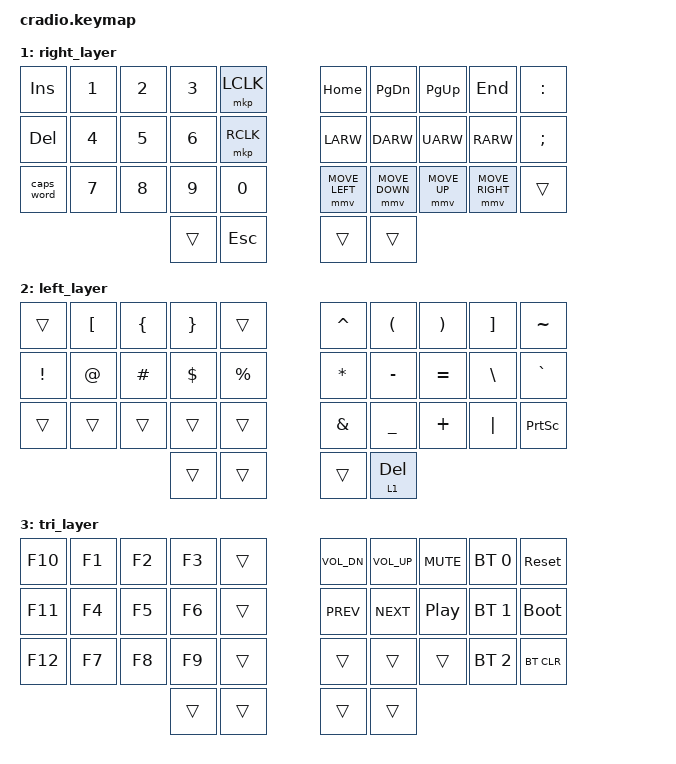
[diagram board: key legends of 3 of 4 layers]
// Copyright (c) 2022 The ZMK Contributors
// SPDX-License-Identifier: MIT

#include <behaviors.dtsi>
#include <dt-bindings/zmk/keys.h>
#include <dt-bindings/zmk/bt.h>
#include <dt-bindings/zmk/pointing.h>

// Home row mods macro
#define HRML(k1,k2,k3,k4) &ht LSHFT k1  &ht LCTRL k2  &ht LALT k3  &ht LGUI k4
#define HRMR(k1,k2,k3,k4) &ht RGUI k1  &ht RALT k2  &ht RCTRL k3  &ht RSHFT k4

/ {
    behaviors {
        ht: hold_tap {
            label = "hold_tap";
            compatible = "zmk,behavior-hold-tap";
            #binding-cells = <2>;
            flavor = "tap-preferred";
            tapping-term-ms = <220>;
            quick-tap-ms = <150>;
            require-prior-idle-ms = <100>;
            bindings = <&kp>, <&kp>;
        };

        // Dead key: send Compose + one key; the next key typed completes it.
        // &dead SQT -> Compose ' -> then e = é, E = É (see ~/.XCompose for n ? ! s)
        dead: dead_key {
            compatible = "zmk,behavior-macro-one-param";
            #binding-cells = <1>;
            bindings
                = <&kp CAPS>
                , <&macro_param_1to1>, <&kp MACRO_PLACEHOLDER>
                ;
        };
    };

    conditional_layers {
        compatible = "zmk,conditional-layers";
        tri_layer {
            if-layers = <1 2>;
            then-layer = <3>;
        };
    };

    combos {
        compatible = "zmk,combos";
        combo_tmux {
            timeout-ms = <50>;
            key-positions = <11 12>;  // S + D = Ctrl+A (tmux prefix)
            bindings = <&kp LC(A)>;
        };
        combo_acute {
            timeout-ms = <50>;
            key-positions = <2 12>;   // E + D = accent: then vowel → á é í ó ú, n → ñ, ? → ¿, ! → ¡
            bindings = <&dead SQT>;
        };
        combo_umlaut {
            timeout-ms = <50>;
            key-positions = <6 16>;   // U + J = umlaut: then vowel → ä ö ü, s → ß
            bindings = <&dead DQT>;
        };
        combo_compose {
            timeout-ms = <50>;
            key-positions = <12 13>;  // D + F = Compose key, for any other Compose sequence
            bindings = <&kp CAPS>;
        };
    };

    keymap {
        compatible = "zmk,keymap";
        default_layer {
            bindings = <
        //╭──────────┬──────────┬──────────┬──────────┬──────────╮   ╭──────────┬──────────┬──────────┬──────────┬──────────╮
        //│  Q       │  W       │  E       │  R       │  T       │   │  Y       │  U       │  I       │  O       │  P       │
            &kp Q      &kp W      &kp E      &kp R      &kp T          &kp Y      &kp U      &kp I      &kp O      &kp P
        //├──────────┼──────────┼──────────┼──────────┼──────────┤   ├──────────┼──────────┼──────────┼──────────┼──────────┤
        //│  A       │  S       │  D       │  F       │  G       │   │  H       │  J       │  K       │  L       │ ' "      │
            HRML(A,        S,         D,         F)     &kp G          &kp H      HRMR(J,        K,         L,        SQT)
        //├──────────┼──────────┼──────────┼──────────┼──────────┤   ├──────────┼──────────┼──────────┼──────────┼──────────┤
        //│  Z       │  X       │  C       │  V       │  B       │   │  N       │  M       │ , <      │ . >      │ / ?      │
            &kp Z      &kp X      &kp C      &kp V      &kp B          &kp N      &kp M      &kp COMMA  &kp DOT    &kp FSLH
        //╰──────────┴──────────┴──────────┼──────────┼──────────┤   ├──────────┼──────────┼──────────┴──────────┴──────────╯
                                            &lt 2 TAB   &kp ENTER     &kp SPACE  &lt 1 BSPC
        //                                 ╰──────────┴──────────╯   ╰──────────┴──────────╯
            >;
        };

        right_layer {
            bindings = <
        //╭──────────┬──────────┬──────────┬──────────┬──────────╮   ╭──────────┬──────────┬──────────┬──────────┬──────────╮
        //│ INSERT   │  1       │  2       │  3       │ LEFT CLK │   │ HOME     │ PAGE DN  │ PAGE UP  │ END      │  :       │
            &kp INS    &kp N1     &kp N2     &kp N3     &mkp LCLK      &kp HOME   &kp PG_DN  &kp PG_UP  &kp END    &kp COLON
        //├──────────┼──────────┼──────────┼──────────┼──────────┤   ├──────────┼──────────┼──────────┼──────────┼──────────┤
        //│ DELETE   │  4       │  5       │  6       │ RIGHT CLK│   │ LEFT     │ DOWN     │ UP       │ RIGHT    │  ;       │
            &kp DEL    &kp N4     &kp N5     &kp N6     &mkp RCLK      &kp LARW   &kp DARW   &kp UARW   &kp RARW   &kp SEMI
        //├──────────┼──────────┼──────────┼──────────┼──────────┤   ├──────────┼──────────┼──────────┼──────────┼──────────┤
        //│ CAPS     │  7       │  8       │  9       │  0       │   │ MS LEFT  │ MS DOWN  │ MS UP    │ MS RIGHT │          │
           &caps_word  &kp N7     &kp N8     &kp N9     &kp N0     &mmv MOVE_LEFT &mmv MOVE_DOWN &mmv MOVE_UP &mmv MOVE_RIGHT &trans
        //╰──────────┴──────────┴──────────┼──────────┼──────────┤   ├──────────┼──────────┼──────────┴──────────┴──────────╯
                                             &trans     &kp ESC        &trans     &trans
        //                                 ╰──────────┴──────────╯   ╰──────────┴──────────╯
            >;
        };

        left_layer {
            bindings = <
        //╭──────────┬──────────┬──────────┬──────────┬──────────╮   ╭──────────┬──────────┬──────────┬──────────┬──────────╮
        //│          │  [       │  {       │  }       │          │   │  ^       │  (       │  )       │  ]       │  ~       │
            &trans     &kp LBKT   &kp LBRC   &kp RBRC   &trans         &kp CARET  &kp LPAR   &kp RPAR   &kp RBKT   &kp TILDE
        //├──────────┼──────────┼──────────┼──────────┼──────────┤   ├──────────┼──────────┼──────────┼──────────┼──────────┤
        //│  !       │  @       │  #       │  $       │  %       │   │  *       │  -       │  =       │  \       │  `       │
            &kp EXCL   &kp AT     &kp HASH   &kp DLLR   &kp PRCNT      &kp ASTRK  &kp MINUS  &kp EQUAL  &kp BSLH   &kp GRAVE
        //├──────────┼──────────┼──────────┼──────────┼──────────┤   ├──────────┼──────────┼──────────┼──────────┼──────────┤
        //│          │          │          │          │          │   │  &       │  _       │  +       │  │       │ PRINT    │
            &trans     &trans     &trans     &trans     &trans         &kp AMPS   &kp UNDER  &kp PLUS   &kp PIPE   &kp PSCRN
        //╰──────────┴──────────┴──────────┼──────────┼──────────┤   ├──────────┼──────────┼──────────┴──────────┴──────────╯
        //                                                                       │ DELETE   │
                                             &trans     &trans         &trans     &lt 1 DEL
        //                                 ╰──────────┴──────────╯   ╰──────────┴──────────╯
            >;
        };

        tri_layer {
            bindings = <
        //╭──────────┬──────────┬──────────┬──────────┬──────────╮   ╭──────────┬──────────┬──────────┬──────────┬──────────╮
        //│ F10      │  F1      │  F2      │  F3      │          │   │ VOL DONW │ VOL UP │  MUTE    │PROFILE 0 │  RESET   │
            &kp F10    &kp F1     &kp F2     &kp F3     &trans         &kp C_VOL_DN &kp C_VOL_UP &kp C_MUTE &bt BT_SEL 0 &sys_reset
        //├──────────┼──────────┼──────────┼──────────┼──────────┤   ├──────────┼──────────┼──────────┼──────────┼──────────┤
        //│ F11      │  F4      │  F5      │  F6      │          │   │ PREV     │ NEXT     │PLAY/PAUSE│PROFILE 1 │BOOTLOADER│
            &kp F11    &kp F4     &kp F5     &kp F6     &trans         &kp C_PREV &kp C_NEXT &kp C_PP &bt BT_SEL 1 &bootloader
        //├──────────┼──────────┼──────────┼──────────┼──────────┤   ├──────────┼──────────┼──────────┼──────────┼──────────┤
        //│ F12      │  F7      │  F8      │  F9      │          │   │          │          │          │PROFILE 2 │ CLEAR BT │
            &kp F12    &kp F7     &kp F8     &kp F9     &trans         &trans     &trans     &trans    &bt BT_SEL 2 &bt BT_CLR
        //╰──────────┴──────────┴──────────┼──────────┼──────────┤   ├──────────┼──────────┼──────────┴──────────┴──────────╯
                                             &trans     &trans         &trans     &trans
        //                                 ╰──────────┴──────────╯   ╰──────────┴──────────╯
            >;
        };
    };
};
